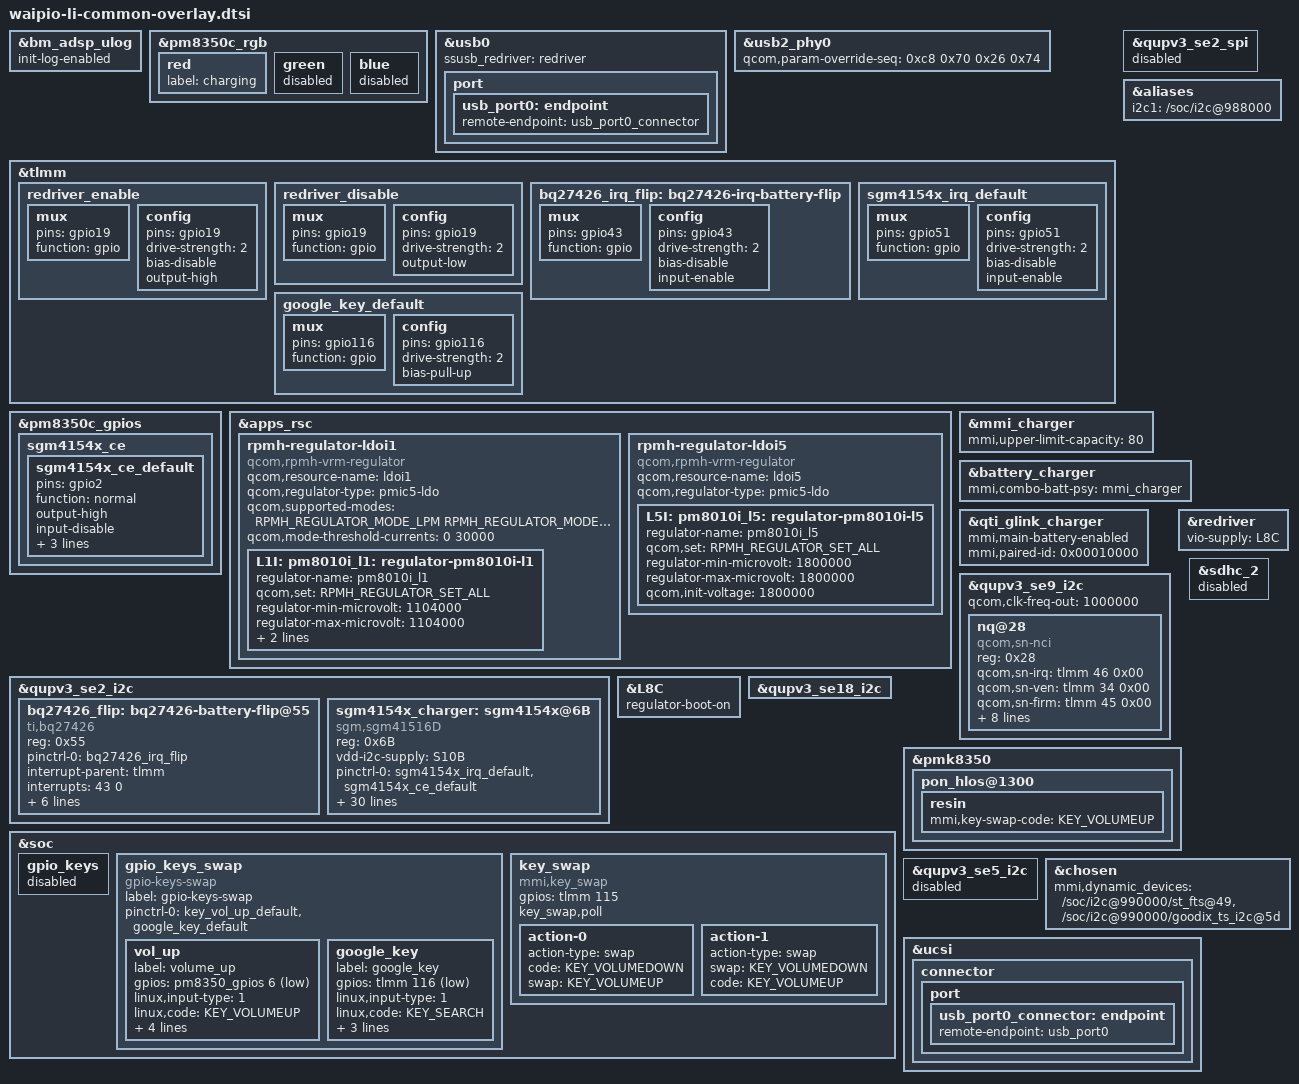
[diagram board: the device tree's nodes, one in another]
/* Copyright (c) 2021, The Linux Foundation. All rights reserved.
 *
 * This program is free software; you can redistribute it and/or modify
 * it under the terms of the GNU General Public License version 2 and
 * only version 2 as published by the Free Software Foundation.
 *
 * This program is distributed in the hope that it will be useful,
 * but WITHOUT ANY WARRANTY; without even the implied warranty of
 * MERCHANTABILITY or FITNESS FOR A PARTICULAR PURPOSE.  See the
 * GNU General Public License for more details.
 */

/*
   This base is original from "waipio-mtp-pm8008-overlay.dts"
*/
#include "waipio-moto-common-overlay-base.dtsi"

#include "waipio-moto-common-overlay.dtsi"
#include "waipio-moto-common-redriver.dtsi"
#include "waipio-hiphi-fingerprint.dtsi"
#include "waipio-li-touchscreen-overlay.dtsi"
#include "waipio-li-haptics-overlay.dtsi"
#include "waipio-moto-common-charger.dtsi"
#include "waipio-li-charger-overlay.dtsi"
#include "waipio-li-thermal-overlay.dtsi"
#include "waipio-pm8010-spmi.dtsi"

&bm_adsp_ulog {
	init-log-enabled;
};

&pm8350c_rgb {
	red {
		label = "charging";
	};

	green {
		status = "disabled";
	};

	blue {
		status = "disabled";
	};
};

&usb0 {
	ssusb_redriver = <&redriver>;

	port {
		usb_port0: endpoint {
			remote-endpoint = <&usb_port0_connector>;
		};
	};
};

&usb2_phy0 {
	qcom,param-override-seq =
		<0xc8 0x70
		0x26 0x74>;
};

&tlmm {
	redriver_enable: redriver_enable {
		mux {
			pins = "gpio19";
			function = "gpio";
		};

		config {
			pins = "gpio19";
			drive-strength = <2>;
			bias-disable; /* NO PULL */
			output-high;
		};
	};
	redriver_disable: redriver_disable {
		mux {
			pins = "gpio19";
			function = "gpio";
		};

		config {
			pins = "gpio19";
			drive-strength = <2>;
			output-low;
		};
	};

	bq27426_irq_flip: bq27426-irq-battery-flip {
		mux {
			pins = "gpio43";
			function = "gpio";
		};

		config {
			pins = "gpio43";
			drive-strength = <2>;
			bias-disable;
			input-enable;
		};
	};

	sgm4154x_irq_default: sgm4154x_irq_default {
		mux {
			pins = "gpio51";
			function = "gpio";
		};

		config {
			pins = "gpio51";
			drive-strength = <2>;
			bias-disable;
			input-enable;
		};
	};
};

&pm8350c_gpios {
	sgm4154x_ce {
		sgm4154x_ce_default: sgm4154x_ce_default {
			pins = "gpio2";
			function = "normal";
			output-high;
                        input-disable;
                        bias-disable;
                        power-source = <0>;       /* GPIO_LV, can be only 0: 1.8V */
                        qcom,drive-strength = <2>;
		};
	};
};

&apps_rsc {
    rpmh-regulator-ldoi1 {
        compatible = "qcom,rpmh-vrm-regulator";
        qcom,resource-name = "ldoi1";
        qcom,regulator-type = "pmic5-ldo";
        qcom,supported-modes =
            <RPMH_REGULATOR_MODE_LPM
             RPMH_REGULATOR_MODE_HPM>;
        qcom,mode-threshold-currents = <0 30000>;
        L1I: pm8010i_l1: regulator-pm8010i-l1 {
            regulator-name = "pm8010i_l1";
            qcom,set = <RPMH_REGULATOR_SET_ALL>;
            regulator-min-microvolt = <1104000>;
            regulator-max-microvolt = <1104000>;
            qcom,init-voltage = <1104000>;
            qcom,init-mode = <RPMH_REGULATOR_MODE_HPM>;
        };
    };

    rpmh-regulator-ldoi5 {
        compatible = "qcom,rpmh-vrm-regulator";
        qcom,resource-name = "ldoi5";
        qcom,regulator-type = "pmic5-ldo";
        L5I: pm8010i_l5: regulator-pm8010i-l5 {
            regulator-name = "pm8010i_l5";
            qcom,set = <RPMH_REGULATOR_SET_ALL>;
            regulator-min-microvolt = <1800000>;
            regulator-max-microvolt = <1800000>;
            qcom,init-voltage = <1800000>;
        };
    };
};

&qupv3_se2_spi {
	status = "disabled";
};

&aliases {
	i2c1 = "/soc/i2c@988000";
};

&qupv3_se2_i2c {
	status = "ok";
	bq27426_flip: bq27426-battery-flip@55 {
		compatible = "ti,bq27426";
		reg = <0x55>;
		pinctrl-names = "default";
		pinctrl-0 = <&bq27426_irq_flip>;
		interrupt-parent = <&tlmm>;
		interrupts = <43 0>;
		vdd-i2c-supply = <&S10B>;
		design-capacity = <712>;
		mmi,fg-psy-name = "flip_battery";
		mmi,batt-profile-name = "NM40_ATL_712MAH";
		mmi,temp-source = <1>;
		mmi,ibat-invert-polority;
	};

	sgm4154x_charger: sgm4154x@6B {
		compatible = "sgm,sgm41516D";
		reg = <0x6B>;

		vdd-i2c-supply = <&S10B>;
		pinctrl-names = "default";
		pinctrl-0 = <&sgm4154x_irq_default &sgm4154x_ce_default>;

		interrupt-parent = <&tlmm>;
		interrupts = <51 0>;		//irq num base on hardware design
		sgm,irq-gpio = <&tlmm 51 0>;	//irq num base on hardware design
		sgm,chg-en-gpio = <&pm8350c_gpios 2 GPIO_ACTIVE_LOW>;	//gpio num base on hardware design

		init-charger-disabled;
		vrechg-millivolt = <200>;
		iprechg-microamp = <180000>;
		iterm-microamp = <200000>;
		ichg-max-microamp = <1200000>;
		vchg-max-microvolt = <4600000>;
		ichg-microamp = <700000>;
		vchg-microvolt = <4400000>;
		input-current-limit-microamp = <1200000>;

		mmi,ext-usb-psy-name = "usb";
		mmi,fg-psy-name = "flip_battery";
		mmi,chrg-iterm-ma = <100>;
		mmi,fg-iterm-ma = <150>;
		mmi,max-fv-mv = <4480>;
		mmi,max-fcc-ma = <1214>;
		mmi,demo-fv-mv = <4000>;
		mmi,df-serialnum = "SB18D44720";
		mmi,mmi-temp-zones = <0 4200 136 0>,
				    <10 4250 340 204>,
				    <15 0 679 476>,
				    <45 4300 1214 883>,
				    <45 4350 883 679>,
				    <60 4200 679 0>;

		mmi,paired-id = <0x00000001>;
		// delta_ocv ichg map table
		mmi,paired-ichg-table = <60 1200
					 90 900
					 120 600
					 150 300>;
		mmi,paired-load-thres = <800 400>;
		mmi,thermal-mitigation = <900000 600000 300000>;
	};
};

&mmi_charger {
	mmi,upper-limit-capacity = <80>;
};

&battery_charger {
	mmi,combo-batt-psy = <&mmi_charger>;
};

&qti_glink_charger {
	mmi,main-battery-enabled;
	mmi,paired-id = <0x00010000>;
};

&qupv3_se9_i2c {
	status = "ok";
	qcom,clk-freq-out = <1000000>;
	#address-cells = <1>;
	#size-cells = <0>;
	nq@28 {
		compatible = "qcom,sn-nci";
		reg = <0x28>;
		qcom,sn-irq = <&tlmm 46 0x00>;
		qcom,sn-ven = <&tlmm 34 0x00>;
		qcom,sn-firm = <&tlmm 45 0x00>;
		qcom,sn-clkreq = <&tlmm 35 0x00>;
		qcom,sn-vdd-1p8-supply = <&S10B>;
		qcom,sn-vdd-1p8-voltage = <1800000 1800000>;
		qcom,sn-vdd-1p8-current = <157000>;
		interrupt-parent = <&tlmm>;
		interrupts = <46 0>;
		interrupt-names = "nfc_irq";
		pinctrl-names = "nfc_active", "nfc_suspend";
		pinctrl-0 = <&nfc_int_active &nfc_enable_active>;
		pinctrl-1 = <&nfc_int_suspend &nfc_enable_suspend>;
	};
};

&L8C {
	regulator-boot-on;
};

&redriver {
	status = "ok";
	vio-supply = <&L8C>;
};

&qupv3_se18_i2c {
	status = "ok";
};

&soc {
	gpio_keys {
		status = "disabled";
	};

	gpio_keys_swap {
		compatible = "gpio-keys-swap";
		label = "gpio-keys-swap";

		pinctrl-names = "default";
		pinctrl-0 = <&key_vol_up_default &google_key_default>;

		vol_up {
			label = "volume_up";
			gpios = <&pm8350_gpios 6 GPIO_ACTIVE_LOW>;
			linux,input-type = <1>;
			linux,code = <KEY_VOLUMEUP>;
			mmi,key-swap-code = <KEY_VOLUMEDOWN>;
			gpio-key,wakeup;
			debounce-interval = <15>;
			linux,can-disable;
		};

		google_key {
			label = "google_key";
			gpios = <&tlmm 116 GPIO_ACTIVE_LOW>;
			linux,input-type = <1>;
			linux,code = <KEY_SEARCH>;
			gpio-key,wakeup;
			debounce-interval = <15>;
			linux,can-disable;
		};
	};

	key_swap {
		compatible = "mmi,key_swap";
		gpios = <&tlmm 115 0>;
		key_swap,poll;
		action-0 {
			action-type = "swap";
			code = <KEY_VOLUMEDOWN>;
			swap = <KEY_VOLUMEUP>;
		};
		action-1 {
			action-type = "swap";
			swap = <KEY_VOLUMEDOWN>;
			code = <KEY_VOLUMEUP>;
		};
	};
};

&pmk8350 {
	pon_hlos@1300 {
		resin {
			mmi,key-swap-code = <KEY_VOLUMEUP>;
		};
	};
};

&tlmm{
	google_key_default: google_key_default {
		mux {
			pins = "gpio116";
			function = "gpio";
		};

		config {
			pins = "gpio116";
			drive-strength = <2>;
			bias-pull-up;
		};
	};
};

&qupv3_se5_i2c {
	status = "disabled";
};

&sdhc_2 {
	status = "disabled";
};

&chosen {
	mmi,dynamic_devices = "/soc/i2c@990000/st_fts@49", "/soc/i2c@990000/goodix_ts_i2c@5d";
};

&ucsi {
	connector {
		port {
			usb_port0_connector: endpoint {
				remote-endpoint = <&usb_port0>;
			};
		};
	};
};
